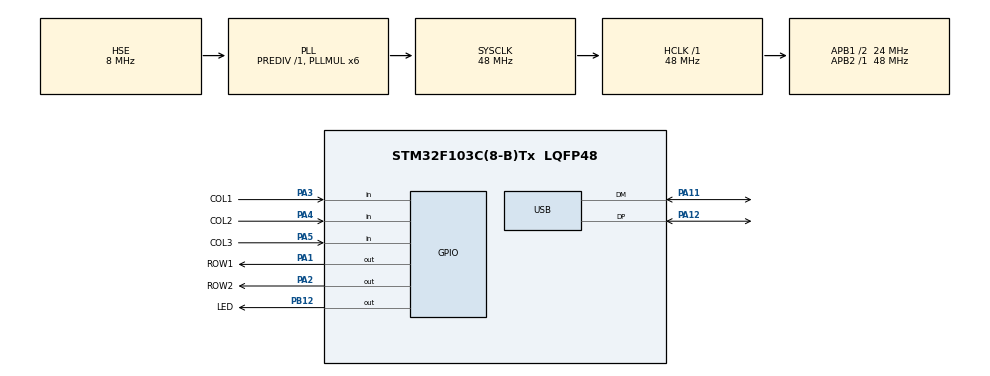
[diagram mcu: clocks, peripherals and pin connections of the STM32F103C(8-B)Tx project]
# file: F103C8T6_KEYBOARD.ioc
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Mcu.Family=STM32F1
Mcu.Name=STM32F103C(8-B)Tx
Mcu.Package=LQFP48
NVIC.PriorityGroup=NVIC_PRIORITYGROUP_4
NVIC.TIM2_IRQn=true\:0\:0\:false\:false\:true\:true\:true\:true
NVIC.USB_LP_CAN1_RX0_IRQn=true\:0\:0\:false\:false\:true\:false\:true\:true
PA1.GPIO_Label=ROW1
PA1.Signal=GPIO_Output
PA11.Mode=Device
PA11.Signal=USB_DM
PA12.Mode=Device
PA12.Signal=USB_DP
PA13.Mode=Serial_Wire
PA13.Signal=SYS_JTMS-SWDIO
PA14.Mode=Serial_Wire
PA14.Signal=SYS_JTCK-SWCLK
PA2.GPIO_Label=ROW2
PA2.Signal=GPIO_Output
PA3.GPIO_Label=COL1
PA3.Signal=GPIO_Input
PA4.GPIO_Label=COL2
PA4.Signal=GPIO_Input
PA5.GPIO_Label=COL3
PA5.Signal=GPIO_Input
PB12.GPIO_Label=LED
PB12.Signal=GPIO_Output
PD0-OSC_IN.Mode=HSE-External-Oscillator
PD0-OSC_IN.Signal=RCC_OSC_IN
PD1-OSC_OUT.Mode=HSE-External-Oscillator
PD1-OSC_OUT.Signal=RCC_OSC_OUT
ProjectManager.HeapSize=0x200
ProjectManager.StackSize=0x400
ProjectManager.TargetToolchain=STM32CubeIDE
RCC.AHBFreq_Value=48000000
RCC.APB1CLKDivider=RCC_HCLK_DIV2
RCC.APB1Freq_Value=24000000
RCC.APB1TimFreq_Value=48000000
RCC.APB2Freq_Value=48000000
RCC.APB2TimFreq_Value=48000000
RCC.HCLKFreq_Value=48000000
RCC.PLLMUL=RCC_PLL_MUL6
RCC.SYSCLKFreq_VALUE=48000000
RCC.SYSCLKSource=RCC_SYSCLKSOURCE_PLLCLK
RCC.USBFreq_Value=48000000
TIM2.Period=20
TIM2.Prescaler=4800-1
USB_DEVICE.CLASS_NAME_FS=HID
USB_DEVICE.PRODUCT_STRING_HID_FS=KBRD
USB_DEVICE.VirtualMode=Hid
USB_DEVICE.VirtualModeFS=Hid_FS
VP_TIM2_VS_ClockSourceINT.Mode=Internal
VP_USB_DEVICE_VS_USB_DEVICE_HID_FS.Mode=HID_FS
board=custom

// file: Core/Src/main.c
/* USER CODE BEGIN Header */
/**
  ******************************************************************************
  * @file           : main.c
  * @brief          : Main program body
  ******************************************************************************
  * @attention
  *
  * Copyright (c) 2024 STMicroelectronics.
  * All rights reserved.
  *
  * This software is licensed under terms that can be found in the LICENSE file
  * in the root directory of this software component.
  * If no LICENSE file comes with this software, it is provided AS-IS.
  *
  ******************************************************************************
  */
/* USER CODE END Header */
#include "main.h"
#include "usb_device.h"

/* USER CODE BEGIN Includes */
#include "keyboard_action.h"
/* USER CODE END Includes */

extern TIM_HandleTypeDef htim2;

/* USER CODE BEGIN PV */
extern USBD_HandleTypeDef hUsbDeviceFS;
keyboardReportDesc HIDkeyboard  = {0,0,0,0,0,0,0,0};
uint16_t timer_200hz;
/* USER CODE END PV */

void SystemClock_Config(void);
static void MX_GPIO_Init(void);
static void MX_TIM2_Init(void);

int main(void)
{

  /* MCU Configuration--------------------------------------------------------*/

  /* Reset of all peripherals, Initializes the Flash interface and the Systick. */
  HAL_Init();

  /* Configure the system clock */
  SystemClock_Config();

  /* Initialize all configured peripherals */
  MX_GPIO_Init();
  MX_USB_DEVICE_Init();
  MX_TIM2_Init();
  /* USER CODE BEGIN 2 */
  HAL_TIM_Base_Start_IT(&htim2);
  /* USER CODE END 2 */

  /* Infinite loop */
  while (1)
  {

    /* USER CODE BEGIN 3 */
	  if (TIMER_COUNT == SET) {
		  TIMER_COUNT = RESET;
		  timer_200hz++;
		  if (timer_200hz == 2) {
			  poll_keyboard();
			  timer_200hz = 0;
		  }
	  }

  }
  /* USER CODE END 3 */
}

void SystemClock_Config(void)
{
  RCC_OscInitTypeDef RCC_OscInitStruct = {0};
  RCC_ClkInitTypeDef RCC_ClkInitStruct = {0};
  RCC_PeriphCLKInitTypeDef PeriphClkInit = {0};

  /** Initializes the RCC Oscillators according to the specified parameters
  * in the RCC_OscInitTypeDef structure.
  */
  RCC_OscInitStruct.OscillatorType = RCC_OSCILLATORTYPE_HSE;
  RCC_OscInitStruct.HSEState = RCC_HSE_ON;
  RCC_OscInitStruct.HSEPredivValue = RCC_HSE_PREDIV_DIV1;
  RCC_OscInitStruct.HSIState = RCC_HSI_ON;
  RCC_OscInitStruct.PLL.PLLState = RCC_PLL_ON;
  RCC_OscInitStruct.PLL.PLLSource = RCC_PLLSOURCE_HSE;
  RCC_OscInitStruct.PLL.PLLMUL = RCC_PLL_MUL6;
  if (HAL_RCC_OscConfig(&RCC_OscInitStruct) != HAL_OK)
  {
    Error_Handler();
  }

  /** Initializes the CPU, AHB and APB buses clocks
  */
  RCC_ClkInitStruct.ClockType = RCC_CLOCKTYPE_HCLK|RCC_CLOCKTYPE_SYSCLK
                              |RCC_CLOCKTYPE_PCLK1|RCC_CLOCKTYPE_PCLK2;
  RCC_ClkInitStruct.SYSCLKSource = RCC_SYSCLKSOURCE_PLLCLK;
  RCC_ClkInitStruct.AHBCLKDivider = RCC_SYSCLK_DIV1;
  RCC_ClkInitStruct.APB1CLKDivider = RCC_HCLK_DIV2;
  RCC_ClkInitStruct.APB2CLKDivider = RCC_HCLK_DIV1;

  if (HAL_RCC_ClockConfig(&RCC_ClkInitStruct, FLASH_LATENCY_1) != HAL_OK)
  {
    Error_Handler();
  }
  PeriphClkInit.PeriphClockSelection = RCC_PERIPHCLK_USB;
  PeriphClkInit.UsbClockSelection = RCC_USBCLKSOURCE_PLL;
  if (HAL_RCCEx_PeriphCLKConfig(&PeriphClkInit) != HAL_OK)
  {
    Error_Handler();
  }
}

static void MX_TIM2_Init(void)
{

  TIM_ClockConfigTypeDef sClockSourceConfig = {0};
  TIM_MasterConfigTypeDef sMasterConfig = {0};

  htim2.Instance = TIM2;
  htim2.Init.Prescaler = 4800-1;
  htim2.Init.CounterMode = TIM_COUNTERMODE_UP;
  htim2.Init.Period = 20;
  htim2.Init.ClockDivision = TIM_CLOCKDIVISION_DIV1;
  htim2.Init.AutoReloadPreload = TIM_AUTORELOAD_PRELOAD_DISABLE;
  if (HAL_TIM_Base_Init(&htim2) != HAL_OK)
  {
    Error_Handler();
  }
  sClockSourceConfig.ClockSource = TIM_CLOCKSOURCE_INTERNAL;
  if (HAL_TIM_ConfigClockSource(&htim2, &sClockSourceConfig) != HAL_OK)
  {
    Error_Handler();
  }
  sMasterConfig.MasterOutputTrigger = TIM_TRGO_RESET;
  sMasterConfig.MasterSlaveMode = TIM_MASTERSLAVEMODE_DISABLE;
  if (HAL_TIMEx_MasterConfigSynchronization(&htim2, &sMasterConfig) != HAL_OK)
  {
    Error_Handler();
  }

}

static void MX_GPIO_Init(void)
{
  GPIO_InitTypeDef GPIO_InitStruct = {0};

  /* GPIO Ports Clock Enable */
  __HAL_RCC_GPIOD_CLK_ENABLE();
  __HAL_RCC_GPIOA_CLK_ENABLE();
  __HAL_RCC_GPIOB_CLK_ENABLE();

  /*Configure GPIO pin Output Level */
  HAL_GPIO_WritePin(GPIOA, ROW1_Pin|ROW2_Pin, GPIO_PIN_RESET);

  /*Configure GPIO pin Output Level */
  HAL_GPIO_WritePin(LED_GPIO_Port, LED_Pin, GPIO_PIN_RESET);

  /*Configure GPIO pins : ROW1_Pin ROW2_Pin */
  GPIO_InitStruct.Pin = ROW1_Pin|ROW2_Pin;
  GPIO_InitStruct.Mode = GPIO_MODE_OUTPUT_PP;
  GPIO_InitStruct.Pull = GPIO_NOPULL;
  GPIO_InitStruct.Speed = GPIO_SPEED_FREQ_LOW;
  HAL_GPIO_Init(GPIOA, &GPIO_InitStruct);

  /*Configure GPIO pins : COL1_Pin COL2_Pin COL3_Pin */
  GPIO_InitStruct.Pin = COL1_Pin|COL2_Pin|COL3_Pin;
  GPIO_InitStruct.Mode = GPIO_MODE_INPUT;
  GPIO_InitStruct.Pull = GPIO_NOPULL;
  HAL_GPIO_Init(GPIOA, &GPIO_InitStruct);

  /*Configure GPIO pin : LED_Pin */
  GPIO_InitStruct.Pin = LED_Pin;
  GPIO_InitStruct.Mode = GPIO_MODE_OUTPUT_PP;
  GPIO_InitStruct.Pull = GPIO_NOPULL;
  GPIO_InitStruct.Speed = GPIO_SPEED_FREQ_LOW;
  HAL_GPIO_Init(LED_GPIO_Port, &GPIO_InitStruct);

}

/* USER CODE BEGIN 4 */
void HAL_TIM_PeriodElapsedCallback(TIM_HandleTypeDef *htim)
{
//	if (htim->Instance == TIM2) {
//		// polling keyboard updates
//		poll_keyboard();
//	}
}
/* USER CODE END 4 */

void Error_Handler(void)
{
  __disable_irq();
  while (1)
  {
  }
}
